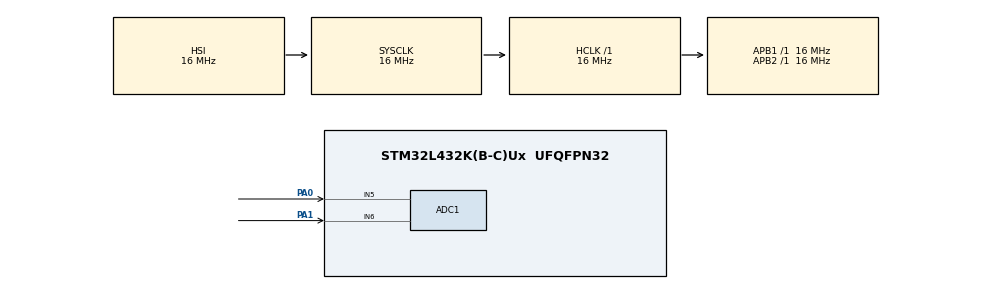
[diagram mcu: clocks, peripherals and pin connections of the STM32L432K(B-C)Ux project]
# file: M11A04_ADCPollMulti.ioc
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ADC1.Channel-3\#ChannelRegularConversion=ADC_CHANNEL_5
ADC1.Channel-4\#ChannelRegularConversion=ADC_CHANNEL_6
ADC1.ContinuousConvMode=ENABLE
ADC1.NbrOfConversion=2
ADC1.NbrOfConversionFlag=1
ADC1.OffsetNumber-3\#ChannelRegularConversion=ADC_OFFSET_NONE
ADC1.OffsetNumber-4\#ChannelRegularConversion=ADC_OFFSET_NONE
ADC1.Rank-3\#ChannelRegularConversion=1
ADC1.Rank-4\#ChannelRegularConversion=2
ADC1.SamplingTime-3\#ChannelRegularConversion=ADC_SAMPLETIME_24CYCLES_5
ADC1.SamplingTime-4\#ChannelRegularConversion=ADC_SAMPLETIME_24CYCLES_5
ADC1.master=1
Mcu.Family=STM32L4
Mcu.Name=STM32L432K(B-C)Ux
Mcu.Package=UFQFPN32
NVIC.PriorityGroup=NVIC_PRIORITYGROUP_4
PA0.Signal=ADCx_IN5
PA1.Signal=ADCx_IN6
ProjectManager.HeapSize=0x200
ProjectManager.StackSize=0x400
ProjectManager.TargetToolchain=STM32CubeIDE
RCC.ADCCLockSelection=RCC_ADCCLKSOURCE_SYSCLK
RCC.ADCFreq_Value=16000000
RCC.AHBFreq_Value=16000000
RCC.APB1Freq_Value=16000000
RCC.APB1TimFreq_Value=16000000
RCC.APB2Freq_Value=16000000
RCC.APB2TimFreq_Value=16000000
RCC.CortexFreq_Value=16000000
RCC.HCLKFreq_Value=16000000
RCC.HSE_VALUE=8000000
RCC.HSI16_VALUE=16000000
RCC.HSI48_VALUE=48000000
RCC.HSI_VALUE=16000000
RCC.LSE_VALUE=32768
RCC.MSI_VALUE=4000000
RCC.PLLMUL=RCC_PLLMUL_4
RCC.PLLN=16
RCC.SYSCLKFreq_VALUE=16000000
RCC.SYSCLKSource=RCC_SYSCLKSOURCE_HSI
RCC.VCOOutputFreq_Value=64000000
SH.ADCx_IN5.0=ADC1_IN5,IN5-Single-Ended
SH.ADCx_IN6.0=ADC1_IN6,IN6-Single-Ended
board=NUCLEO-L432KC

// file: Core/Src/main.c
/* USER CODE BEGIN Header */
/**
 ******************************************************************************
 * @file           : main.c
 * @brief          : Main program body
 ******************************************************************************
 * @attention
 *
 * Copyright (c) 2023 STMicroelectronics.
 * All rights reserved.
 *
 * This software is licensed under terms that can be found in the LICENSE file
 * in the root directory of this software component.
 * If no LICENSE file comes with this software, it is provided AS-IS.
 *
 ******************************************************************************
 */
/* USER CODE END Header */
#include "main.h"
#include "adc.h"
#include "gpio.h"

/* USER CODE BEGIN PV */
uint16_t data1;
uint16_t data2;
/* USER CODE END PV */

void SystemClock_Config(void);

int main(void) {

	/* MCU Configuration--------------------------------------------------------*/

	/* Reset of all peripherals, Initializes the Flash interface and the Systick. */
	HAL_Init();

	/* Configure the system clock */
	SystemClock_Config();

	/* Initialize all configured peripherals */
	MX_GPIO_Init();
	MX_ADC1_Init();

	/* Infinite loop */
	/* USER CODE BEGIN WHILE */
	while (1) {
		HAL_ADC_Start(&hadc1);

		HAL_ADC_PollForConversion(&hadc1, 100);
		data1 = HAL_ADC_GetValue(&hadc1);

		HAL_ADC_PollForConversion(&hadc1, 100);
		data2 = HAL_ADC_GetValue(&hadc1);

		HAL_ADC_Stop(&hadc1);
		/* USER CODE END WHILE */

	}
}

void SystemClock_Config(void) {
	RCC_OscInitTypeDef RCC_OscInitStruct = { 0 };
	RCC_ClkInitTypeDef RCC_ClkInitStruct = { 0 };

	/** Configure the main internal regulator output voltage
	 */
	if (HAL_PWREx_ControlVoltageScaling(PWR_REGULATOR_VOLTAGE_SCALE1)
			!= HAL_OK) {
		Error_Handler();
	}

	/** Initializes the RCC Oscillators according to the specified parameters
	 * in the RCC_OscInitTypeDef structure.
	 */
	RCC_OscInitStruct.OscillatorType = RCC_OSCILLATORTYPE_HSI;
	RCC_OscInitStruct.HSIState = RCC_HSI_ON;
	RCC_OscInitStruct.HSICalibrationValue = RCC_HSICALIBRATION_DEFAULT;
	RCC_OscInitStruct.PLL.PLLState = RCC_PLL_NONE;
	if (HAL_RCC_OscConfig(&RCC_OscInitStruct) != HAL_OK) {
		Error_Handler();
	}

	/** Initializes the CPU, AHB and APB buses clocks
	 */
	RCC_ClkInitStruct.ClockType = RCC_CLOCKTYPE_HCLK | RCC_CLOCKTYPE_SYSCLK
			| RCC_CLOCKTYPE_PCLK1 | RCC_CLOCKTYPE_PCLK2;
	RCC_ClkInitStruct.SYSCLKSource = RCC_SYSCLKSOURCE_HSI;
	RCC_ClkInitStruct.AHBCLKDivider = RCC_SYSCLK_DIV1;
	RCC_ClkInitStruct.APB1CLKDivider = RCC_HCLK_DIV1;
	RCC_ClkInitStruct.APB2CLKDivider = RCC_HCLK_DIV1;

	if (HAL_RCC_ClockConfig(&RCC_ClkInitStruct, FLASH_LATENCY_0) != HAL_OK) {
		Error_Handler();
	}
}

void Error_Handler(void) {
	__disable_irq();
	while (1) {
	}
}
